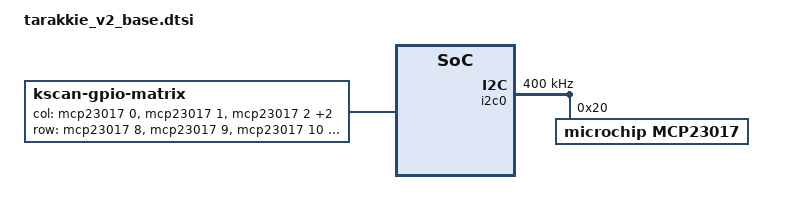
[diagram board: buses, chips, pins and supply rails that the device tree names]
/*
 * Copyright (c) 2025 The ZMK Contributors
 *
 * SPDX-License-Identifier: MIT
 */

#include "tarakkie_v2.dtsi"

/ {
    chosen {
        zmk,kscan = &kscan0;
        zmk,matrix_transform = &default_transform;
    };

    kscan0: kscan_0 {
        compatible = "zmk,kscan-gpio-matrix";
        label = "KSCAN";
        diode-direction = "col2row";

        col-gpios
            = <&mcp23017 0 GPIO_ACTIVE_HIGH> // GPA0
            , <&mcp23017 1 GPIO_ACTIVE_HIGH> // GPA1
            , <&mcp23017 2 GPIO_ACTIVE_HIGH> // GPA2
            , <&mcp23017 3 GPIO_ACTIVE_HIGH> // GPA3
            , <&mcp23017 4 GPIO_ACTIVE_HIGH> // GPA4
            ;

        row-gpios
            = <&mcp23017 8 (GPIO_ACTIVE_HIGH | GPIO_PULL_DOWN)>  // GPB0
            , <&mcp23017 9 (GPIO_ACTIVE_HIGH | GPIO_PULL_DOWN)>  // GPB1
            , <&mcp23017 10 (GPIO_ACTIVE_HIGH | GPIO_PULL_DOWN)> // GPB2
            , <&mcp23017 11 (GPIO_ACTIVE_HIGH | GPIO_PULL_DOWN)> // GPB3
            , <&mcp23017 12 (GPIO_ACTIVE_HIGH | GPIO_PULL_DOWN)> // GPB4
            , <&mcp23017 13 (GPIO_ACTIVE_HIGH | GPIO_PULL_DOWN)> // GPB5
            ;
    };
};

&i2c0 {
    status = "okay";
    pinctrl-0 = <&i2c0_default>;
    pinctrl-1 = <&i2c0_sleep>;
    pinctrl-names = "default", "sleep";
    clock-frequency = <I2C_BITRATE_FAST>;

    mcp23017: mcp23017@20 {
        compatible = "microchip,mcp23017";
        status = "okay";
        reg = <0x20>;
        gpio-controller;
        #gpio-cells = <2>;
    };
};
